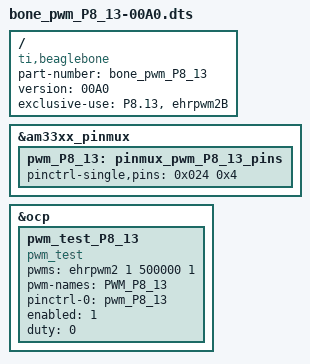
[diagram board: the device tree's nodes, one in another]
/*
 * Copyright (C) 2013 CircuitCo
 * Copyright (C) 2013 Texas Instruments
 *
 * This program is free software; you can redistribute it and/or modify
 * it under the terms of the GNU General Public License version 2 as
 * published by the Free Software Foundation.
 */
/dts-v1/;
/plugin/;

/ {
	compatible = "ti,beaglebone", "ti,beaglebone-black";

	/* identification */
	part-number = "bone_pwm_P8_13";
	version = "00A0";

	/* state the resources this cape uses */
	exclusive-use =
		/* the pin header uses */
		"P8.13",		/* pwm: ehrpwm2B */
		/* the hardware IP uses */
		"ehrpwm2B";

	fragment@0 {
		target = <&am33xx_pinmux>;
		__overlay__ {
			pwm_P8_13: pinmux_pwm_P8_13_pins {
				pinctrl-single,pins = <0x024  0x4>; /* P8_13 (ZCZ ball T10) | MODE 4 */
			};
		};
	};

	fragment@1 {
		target = <&ocp>;
		__overlay__ {
			pwm_test_P8_13 {
				compatible	= "pwm_test";
				pwms 		= <&ehrpwm2 1 500000 1>;
				pwm-names 	= "PWM_P8_13";

				pinctrl-names	= "default";
				pinctrl-0	= <&pwm_P8_13>;

				enabled		= <1>;
				duty		= <0>;
				status 		= "okay";
			};
		};
	};
};
